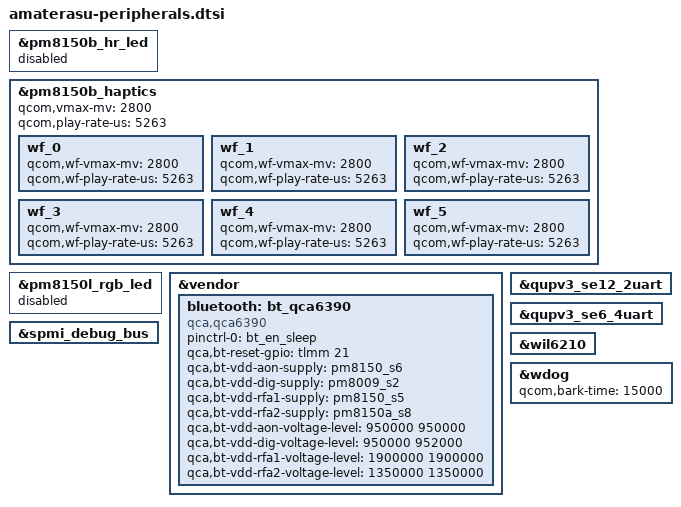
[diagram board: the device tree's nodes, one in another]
/*
 * FCNT arrows 5G (F-51A) - Peripherals: haptics, LEDs, Bluetooth, UARTs, debug and watchdog.
 *
 * Reconstructed from the FCNT stock dtbo (kona FFRD REV7 SKU3); FFRD is
 * derived from the CLO kona QRD board files.
 */

&pm8150b_hr_led {
	status = "disabled";
};

&pm8150b_haptics {
	qcom,vmax-mv = <2800>;
	qcom,play-rate-us = <5263>;

	wf_0 {
		qcom,wf-vmax-mv = <2800>;
		qcom,wf-play-rate-us = <5263>;
	};

	wf_1 {
		qcom,wf-vmax-mv = <2800>;
		qcom,wf-play-rate-us = <5263>;
	};

	wf_2 {
		qcom,wf-vmax-mv = <2800>;
		qcom,wf-play-rate-us = <5263>;
	};

	wf_3 {
		qcom,wf-vmax-mv = <2800>;
		qcom,wf-play-rate-us = <5263>;
	};

	wf_4 {
		qcom,wf-vmax-mv = <2800>;
		qcom,wf-play-rate-us = <5263>;
	};

	wf_5 {
		qcom,wf-vmax-mv = <2800>;
		qcom,wf-play-rate-us = <5263>;
	};
};

&pm8150l_rgb_led {
	status = "disabled";
};

&vendor {
	bluetooth: bt_qca6390 {
		compatible = "qca,qca6390";
		pinctrl-names = "default";
		pinctrl-0 = <&bt_en_sleep>;
		qca,bt-reset-gpio = <&tlmm 21 0>;
		qca,bt-vdd-aon-supply = <&pm8150_s6>;
		qca,bt-vdd-dig-supply = <&pm8009_s2>;
		qca,bt-vdd-rfa1-supply = <&pm8150_s5>;
		qca,bt-vdd-rfa2-supply = <&pm8150a_s8>;
		qca,bt-vdd-aon-voltage-level = <950000 950000>;
		qca,bt-vdd-dig-voltage-level = <950000 952000>;
		qca,bt-vdd-rfa1-voltage-level = <1900000 1900000>;
		qca,bt-vdd-rfa2-voltage-level = <1350000 1350000>;
	};
};

&qupv3_se12_2uart {
	status = "okay";
};

&qupv3_se6_4uart {
	status = "ok";
};

&spmi_debug_bus {
	status = "ok";
};

&wil6210 {
	status = "ok";
};

&wdog {
	qcom,bark-time = <15000>;
};
